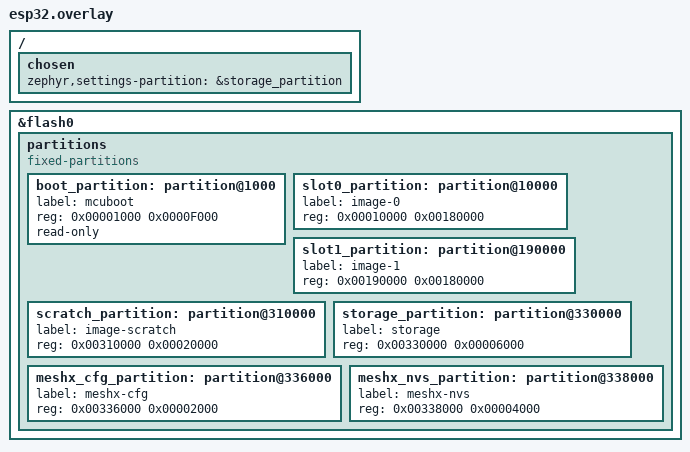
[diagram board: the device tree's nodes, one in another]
/*
 * Copyright (c) 2024 - 2026 MeshX
 * SPDX-License-Identifier: Apache-2.0
 *
 * Common MCU-level DeviceTree Overlay for ESP32 (Xtensa Dual-Core, 4MB Flash).
 * Allocates dedicated partitions matching MeshX partition requirements.
 */

/ {
	chosen {
		zephyr,settings-partition = &storage_partition;
	};
};

&flash0 {
	partitions {
		compatible = "fixed-partitions";
		#address-cells = <1>;
		#size-cells = <1>;

		/* Delete default board partitions that conflict with new offsets */
		/delete-node/ partition@110000;
		/delete-node/ partition@210000;
		/delete-node/ partition@250000;

		/* MCUboot Bootloader (60 KB at 0x1000) */
		boot_partition: partition@1000 {
			label = "mcuboot";
			reg = <0x00001000 0x0000F000>;
			read-only;
		};

		/* Primary Application Image Slot (1536 KB) */
		slot0_partition: partition@10000 {
			label = "image-0";
			reg = <0x00010000 0x00180000>;
		};

		/* Secondary Application Image Slot for Firmware OTA (1536 KB) */
		slot1_partition: partition@190000 {
			label = "image-1";
			reg = <0x00190000 0x00180000>;
		};

		/* MCUboot Swap Scratch Space (128 KB) */
		scratch_partition: partition@310000 {
			label = "image-scratch";
			reg = <0x00310000 0x00020000>;
		};

		/* Bluetooth Mesh & System Settings Partition (24 KB) */
		storage_partition: partition@330000 {
			label = "storage";
			reg = <0x00330000 0x00006000>;
		};

		/* Dedicated MeshX Protobuf Configuration Partition (8 KB) */
		meshx_cfg_partition: partition@336000 {
			label = "meshx-cfg";
			reg = <0x00336000 0x00002000>;
		};

		/* Dedicated MeshX Application NVS Partition (16 KB) */
		meshx_nvs_partition: partition@338000 {
			label = "meshx-nvs";
			reg = <0x00338000 0x00004000>;
		};
	};
};
